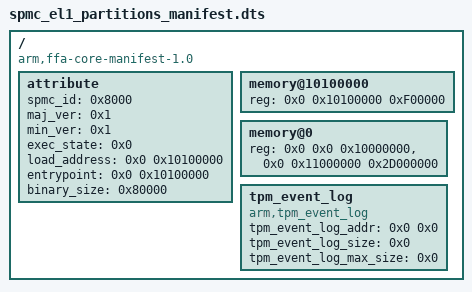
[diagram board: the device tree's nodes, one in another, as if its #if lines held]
/* SPDX-License-Identifier: BSD-3-Clause */
/*
 * Copyright (c) 2026, Arm Limited. All rights reserved.
 */

/dts-v1/;

/ {
	compatible = "arm,ffa-core-manifest-1.0";
	#address-cells = <2>;
	#size-cells = <1>;

	attribute {
		spmc_id = <0x8000>;
		maj_ver = <0x1>;
		min_ver = <0x1>;
		exec_state = <0x0>;
		load_address = <0x0 0x10100000>;
		entrypoint = <0x0 0x10100000>;
		binary_size = <0x80000>;
	};

	/* Secure world memory */
	memory@10100000 {
		device_type = "memory";
		reg = <0x0 0x10100000 0xF00000>; /* Trusted DRAM (from platform_def.h) */
	};

	/* Non secure memory (SPMC needs to know for shared memory setup) */
	memory@0 {
		device_type = "ns-memory";
		reg = <0x0 0x0 0x10000000>, /* Non-secure DRAM (Before "Trusted" DRAM) */
			<0x0 0x11000000 0x2D000000>; /* Non-secure DRAM (After "Trusted" DRAM) */
	};

/*
 * This file will be preprocessed by TF-A's build system. If Measured Boot is
 * enabled in TF-A's config, the build system will add the MEASURED_BOOT=1 macro
 * to the preprocessor arguments.
 */
#if MEASURED_BOOT
	tpm_event_log {
		compatible = "arm,tpm_event_log";
		tpm_event_log_addr = <0x0 0x0>;
		tpm_event_log_size = <0x0>;
		tpm_event_log_max_size = <0x0>;
	};
#endif
};
